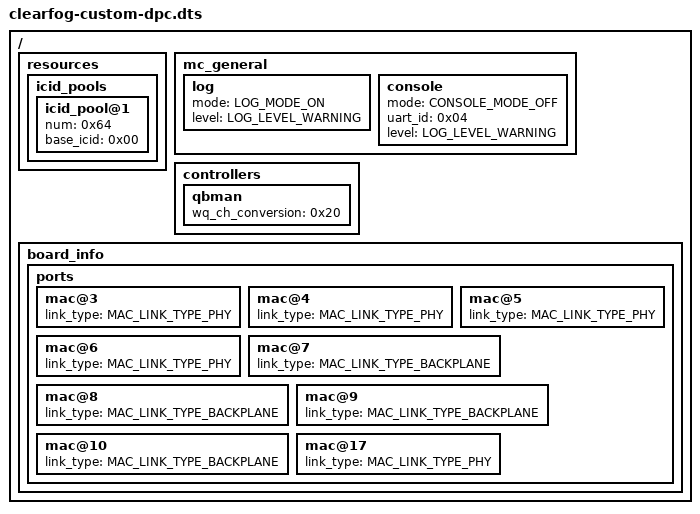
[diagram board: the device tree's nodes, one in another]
/dts-v1/;

/ {
	resources {
		icid_pools {
			icid_pool@1 {
				num = <0x64>;
				base_icid = <0x00>;
			};
		};
	};

	mc_general {
		log {
			mode = "LOG_MODE_ON";
			level = "LOG_LEVEL_WARNING";
		};

		console {
			mode = "CONSOLE_MODE_OFF";
			uart_id = <0x04>;
			level = "LOG_LEVEL_WARNING";
		};
	};

	controllers {
		qbman {
			wq_ch_conversion = <0x20>;
		};
	};

	board_info {
		ports {
			mac@3 {
				link_type = "MAC_LINK_TYPE_PHY";
			};

			mac@4 {
				link_type = "MAC_LINK_TYPE_PHY";
			};

			mac@5 {
				link_type = "MAC_LINK_TYPE_PHY";
			};

			mac@6 {
				link_type = "MAC_LINK_TYPE_PHY";
			};

			mac@7 {
				link_type = "MAC_LINK_TYPE_BACKPLANE";
			};

			mac@8 {
				link_type = "MAC_LINK_TYPE_BACKPLANE";
			};

			mac@9 {
				link_type = "MAC_LINK_TYPE_BACKPLANE";
			};

			mac@10 {
				link_type = "MAC_LINK_TYPE_BACKPLANE";
			};

			mac@17 {
				link_type = "MAC_LINK_TYPE_PHY";
			};
		};
	};
};
